# pse84_a0 register map
Vendor: Infineon Technologies; Series: PSE84_A0; File version: 1.0
CPU: CM33 r0p1, little endian, MPU, FPU, VTOR, 3 interrupt priority bits
Registers are 32-bit, read-write, reset 0x0 unless marked. A register's access mark holds for its fields unless they carry their own. Offsets are from the block's base; [hi:lo] are bit positions; {n}, {i} and the like mark numbered series; 'fields as' and 'values as' point back to an identical list.

## RAMC_PPU0 — Power Policy Unit Registers for System RAM
Base 0x42220000
Same registers: RAMC_PPU1 0x42221000
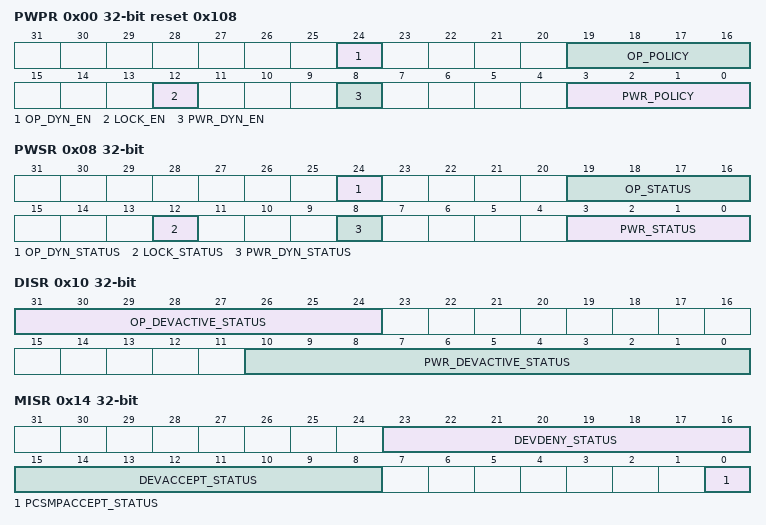
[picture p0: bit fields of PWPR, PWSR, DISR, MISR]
0x00 PWPR reset 0x108 — Power Policy Register
  [24] OP_DYN_EN
  [19:16] OP_POLICY
  [12] LOCK_EN
  [8] PWR_DYN_EN — Power mode dynamic transition enable. When this bit is set to 1 dynamic transitions are enabled for power modes, allowing transitions to be initiated by changes on power mode DEVACTIVE inputs.
  [3:0] PWR_POLICY — Power mode policy. When static power mode transitions are enabled, PWR_DYN_EN is set to 0, this is the target power mode for the PPU. When dynamic power mode transitions are enabled, PWR_DYN_EN is set to 1, this is the minimum power mode for the PPU. This PPU supports the following modes: OFF(0), MEM_RET(2), ON(8). Do not use WARM_RST(9) or other unsupported modes.
0x04 PMER — Power Mode Emulation Register
  [0] EMU_EN
0x08 PWSR ro — Power Status Register
  [24] OP_DYN_STATUS
  [19:16] OP_STATUS
  [12] LOCK_STATUS
  [8] PWR_DYN_STATUS — Power mode dynamic transition status. When set to 1 power mode dynamic transitions are enabled. There might be a delay in dynamic transitions becoming active or inactive if the PPU is transitioning when PWR_DYN_EN is programmed.
  [3:0] PWR_STATUS — Power mode status. These bits reflect the current power mode of the PPU. See PPU_PWPR.PWR_POLICY for power mode enumeration.
0x10 DISR ro — Device Interface Input Current Status Register
  [31:24] OP_DEVACTIVE_STATUS
  [10:0] PWR_DEVACTIVE_STATUS — Status of the power mode DEVACTIVE inputs. There is one bit for each device interface Q-Channel DEVQACTIVE. For example, bit 0 is for Q-channel device 0 DEVQACTIVE. Refer to PPU_IDR0.DEVCHAN for device channel enumeration.
0x14 MISR ro — Miscellaneous Input Current Status Register
  [23:16] DEVDENY_STATUS — Status of the device interface DEVDENY inputs. There is one bit for each device interface DEVQDENY. For example, bit 16 is for Q-Channel 0 DEVQDENY, and bit 17 for Q-Channel 1 DEVQDENY. Refer to PPU_IDR0.DEVCHAN for device channel enumeration.
  [15:8] DEVACCEPT_STATUS — Status of the device interface DEVACCEPT inputs. There is one bit for each device interface DEVQACCEPTn. For example, bit 8 is for Q-Channel 0 DEVQACCEPTn and bit 9 for Q-Channel 1 DEVQACCEPTn. Refer to PPU_IDR0.DEVCHAN for device channel enumeration.
  [0] PCSMPACCEPT_STATUS — The status of the PCSMPACCEPT input.
0x18 STSR ro — Stored Status Register
  [7:0] STORED_DEVDENY
0x1C UNLK — Unlock register
  [0] UNLOCK
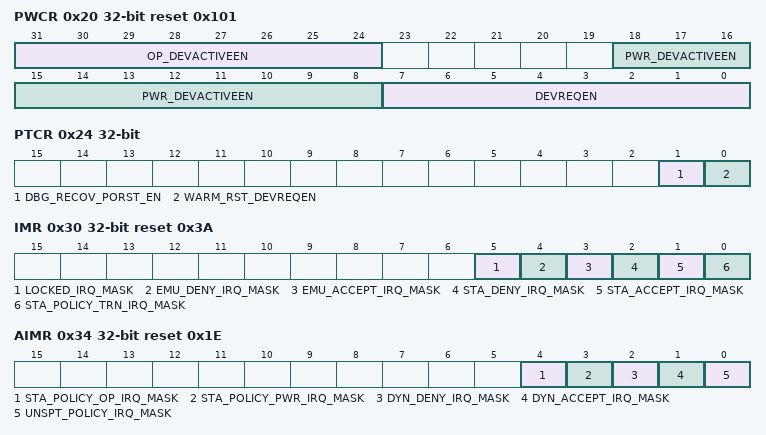
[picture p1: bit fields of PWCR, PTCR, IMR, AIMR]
0x20 PWCR reset 0x101 — Power Configuration Register
  [31:24] OP_DEVACTIVEEN
  [18:8] PWR_DEVACTIVEEN — These bits enable the power mode DEVACTIVE inputs. When a bit is to 1 the related DEVACTIVE input is enabled, when set to 0 it is disabled. All available bits are reset to 1. There is one bit for each device interface Q-Channel DEVQACTIVE. For example, bit 8 is for the Q-Channel 0 DEVQACTIVE, and bit 9 for the Q-Channel 1 DEVQACTIVE. Refer to PPU_IDR0.DEVCHAN for device channel enumeration.
  [7:0] DEVREQEN — When set to 1 enables the device interface handshake for transitions. All available bits are reset to 1. There is one bit for each device interface channel. For example, bit 0 is for Q-Channel 0, and bit 1 is for Q-Channel 1. Refer to PPU_IDR0.DEVCHAN for device channel enumeration.
0x24 PTCR — Power Mode Transition Configuration Register
  [1] DBG_RECOV_PORST_EN
  [0] WARM_RST_DEVREQEN — Transition behavior between ON and WARM_RST. This bit should not be modified when the PPU is in WARM_RST, or if the PPU is performing a transition, otherwise PPU behavior is UNPREDICTABLE. 0: The PPU does not perform a device interface handshake when transitioning between ON and WARM_RST. 1: The PPU performs a device interface handshake when transitioning between ON and WARM_RST. This disables all Q-Channels for this transition.
0x30 IMR reset 0x3A — Interrupt Mask Register
  [5] LOCKED_IRQ_MASK
  [4] EMU_DENY_IRQ_MASK
  [3] EMU_ACCEPT_IRQ_MASK
  [2] STA_DENY_IRQ_MASK — Static transition denial event mask.
  [1] STA_ACCEPT_IRQ_MASK — Static transition acceptance event mask.
  [0] STA_POLICY_TRN_IRQ_MASK — Static full policy transition completion event mask.
0x34 AIMR reset 0x1E — Additional Interrupt Mask Register
  [4] STA_POLICY_OP_IRQ_MASK
  [3] STA_POLICY_PWR_IRQ_MASK
  [2] DYN_DENY_IRQ_MASK — Dynamic transition denial event mask.
  [1] DYN_ACCEPT_IRQ_MASK — Dynamic transition acceptance event mask.
  [0] UNSPT_POLICY_IRQ_MASK — Unsupported Policy event mask.
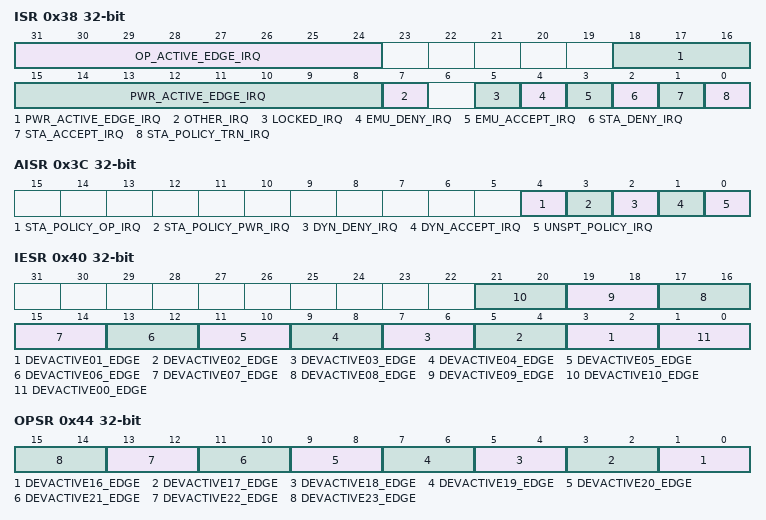
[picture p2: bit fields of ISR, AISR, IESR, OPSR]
0x38 ISR — Interrupt Status Register
  [31:24] OP_ACTIVE_EDGE_IRQ
  [18:8] PWR_ACTIVE_EDGE_IRQ
  [7] OTHER_IRQ ro — Indicates there is an interrupt event pending in the Additional Interrupt Status Register (PPU_AISR).
  [5] LOCKED_IRQ
  [4] EMU_DENY_IRQ
  [3] EMU_ACCEPT_IRQ
  [2] STA_DENY_IRQ — Static transition denial event status.
  [1] STA_ACCEPT_IRQ — Static transition acceptance event status.
  [0] STA_POLICY_TRN_IRQ — Static full policy transition completion event status.
0x3C AISR — Additional Interrupt Status Register
  [4] STA_POLICY_OP_IRQ
  [3] STA_POLICY_PWR_IRQ
  [2] DYN_DENY_IRQ — Dynamic transition denial event status.
  [1] DYN_ACCEPT_IRQ — Dynamic transition acceptance event status.
  [0] UNSPT_POLICY_IRQ — Unsupported Policy event status.
0x40 IESR — Input Edge Sensitivity Register
  [2n+1:2n] DEVACTIVE{n:02}_EDGE (n=1..10)
  [1:0] DEVACTIVE00_EDGE — DEVACTIVE 0 edge sensitivity.
0x44 OPSR — Operating Mode Active Edge Sensitivity Register
  [2n-31:2n-32] DEVACTIVE{n}_EDGE (n=16..23)
0x50 FUNRR — Functional Retention RAM Configuration Register
  [7:0] FUNC_RET_RAM_CFG
0x54 FULRR — Full Retention RAM Configuration Register
  [7:0] FULL_RET_RAM_CFG
0x58 MEMRR — Memory Retention RAM Configuration Register
  [7:0] MEM_RET_RAM_CFG
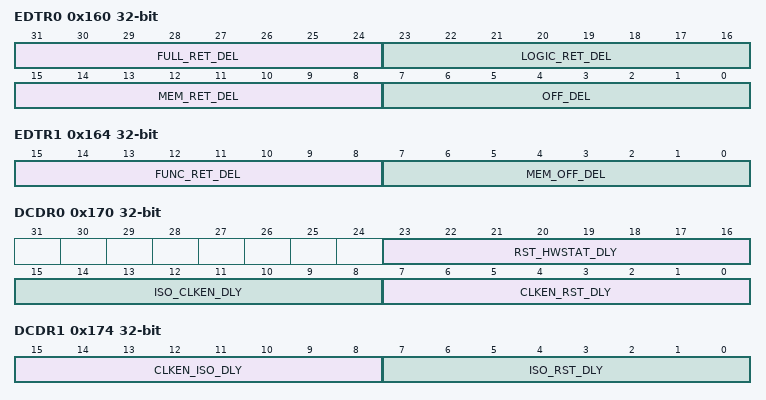
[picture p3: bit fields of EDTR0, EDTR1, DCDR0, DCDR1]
0x160 EDTR0 — Power Mode Entry Delay Register 0
  [31:24] FULL_RET_DEL, [23:16] LOGIC_RET_DEL, [15:8] MEM_RET_DEL, [7:0] OFF_DEL
0x164 EDTR1 — Power Mode Entry Delay Register 1
  [15:8] FUNC_RET_DEL, [7:0] MEM_OFF_DEL
0x170 DCDR0 ro — Device Control Delay Configuration Register 0
  [23:16] RST_HWSTAT_DLY, [15:8] ISO_CLKEN_DLY, [7:0] CLKEN_RST_DLY
0x174 DCDR1 ro — Device Control Delay Configuration Register 1
  [15:8] CLKEN_ISO_DLY, [7:0] ISO_RST_DLY
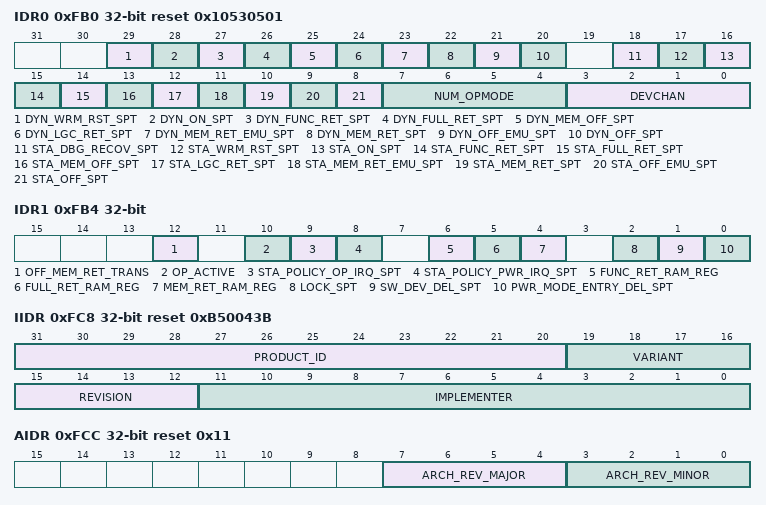
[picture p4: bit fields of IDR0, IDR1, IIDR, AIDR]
0xFB0 IDR0 ro reset 0x10530501 — PPU Identification Register 0
  [29] DYN_WRM_RST_SPT — Dynamic WARM_RST support.
  [28] DYN_ON_SPT — Dynamic ON support.
  [27] DYN_FUNC_RET_SPT — Dynamic FUNC_RET support.
  [26] DYN_FULL_RET_SPT — Dynamic FULL_RET support.
  [25] DYN_MEM_OFF_SPT — Dynamic MEM_OFF support.
  [24] DYN_LGC_RET_SPT — Dynamic LOGIC_RET support.
  [23] DYN_MEM_RET_EMU_SPT — Dynamic MEM_RET_EMU support
  [22] DYN_MEM_RET_SPT — Dynamic MEM_RET support.
  [21] DYN_OFF_EMU_SPT — Dynamic OFF_EMU support.
  [20] DYN_OFF_SPT — Dynamic OFF support.
  [18] STA_DBG_RECOV_SPT — DBG_RECOV support.
  [17] STA_WRM_RST_SPT — WARM_RST support. Ignore this bit. Do not use WARM_RST.
  [16] STA_ON_SPT — ON support.
  [15] STA_FUNC_RET_SPT — FUNC_RET support.
  [14] STA_FULL_RET_SPT — FULL_RET support.
  [13] STA_MEM_OFF_SPT — MEM_OFF support.
  [12] STA_LGC_RET_SPT — LOGIC_RET support.
  [11] STA_MEM_RET_EMU_SPT — MEM_RET_EMU support.
  [10] STA_MEM_RET_SPT — MEM_RET support.
  [9] STA_OFF_EMU_SPT — OFF_EMU support.
  [8] STA_OFF_SPT — OFF support.
  [7:4] NUM_OPMODE — No. of operating modes supported is NUM_OPMODE + 1.
  [3:0] DEVCHAN — No. of Device Interface Channels. The device enumeration is: Device 0: PDCM
0xFB4 IDR1 ro — PPU Identification Register 1
  [12] OFF_MEM_RET_TRANS — OFF to MEM_RET direct transition. Indicates if direct transitions from OFF to MEM_RET and from OFF_EMU to MEM_RET_EMU are supported.
  [10] OP_ACTIVE
  [9] STA_POLICY_OP_IRQ_SPT — Operating policy transition completion event status.
  [8] STA_POLICY_PWR_IRQ_SPT — Power policy transition completion event status.
  [6] FUNC_RET_RAM_REG
  [5] FULL_RET_RAM_REG
  [4] MEM_RET_RAM_REG
  [2] LOCK_SPT — Lock and the lock interrupt event are supported.
  [1] SW_DEV_DEL_SPT — Software device delay control configuration support.
  [0] PWR_MODE_ENTRY_DEL_SPT — Power mode entry delay support.
0xFC8 IIDR ro reset 0xB50043B — Implementation Identification Register
  [31:20] PRODUCT_ID — PPU part identification.
  [19:16] VARIANT — Major revision of the product.
  [15:12] REVISION — Minor revision of the product.
  [11:0] IMPLEMENTER — Implementer identification. [11:8] The JEP106 continuation code of the implementer. [7] Always 0. [6:0] The JEP106 identity code of the implementer. For an Arm implementation, bits [11:0] are 0x43B.
0xFCC AIDR ro reset 0x11 — Architecture Identification Register
  [7:4] ARCH_REV_MAJOR, [3:0] ARCH_REV_MINOR
0xFD0 PID4 ro reset 0x4 — Implementation Defined Identification Register (PID4)
  [3:0] IMPLEMENTER_11_8 — The JEP106 continuation code of the implementer, which is 0x4 hardcoded value.
0xFE0 PID0 ro reset 0xB5 — Implementation Defined Identification Register (PID0)
  [7:0] PRODUCT_ID_7_0 — PPU part identification bits [7:0].
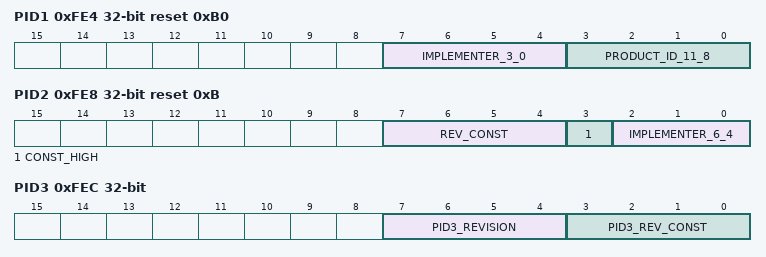
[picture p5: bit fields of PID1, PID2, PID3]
0xFE4 PID1 ro reset 0xB0 — Implementation Defined Identification Register (PID1)
  [7:4] IMPLEMENTER_3_0 — JEP106_ID bits [3:0]
  [3:0] PRODUCT_ID_11_8 — PPU part identification bits [11:8]
0xFE8 PID2 ro reset 0xB — Implementation Defined Identification Register (PID2)
  [7:4] REV_CONST — Constant LOW Revision (4 bits)
  [3] CONST_HIGH — Constant HIGH
  [2:0] IMPLEMENTER_6_4 — JEP106_ID bits [6:4]
0xFEC PID3 ro — Implementation Defined Identification Register (PID3)
  [7:4] PID3_REVISION — Minor revision of the product.
  [3:0] PID3_REV_CONST — Constant LOW (4 bits)
0xFF0 ID0 ro reset 0xD — Implementation Defined Identification Register (ID0)
  [7:0] ID0 — ID0 hard coded value
0xFF4 ID1 ro reset 0xF0 — Implementation Defined Identification Register (ID1)
  [7:0] ID1 — ID1 hardcoded value
0xFF8 ID2 ro reset 0x5 — Implementation Defined Identification Register (ID2)
  [7:0] ID2 — ID2 hardcoded value
0xFFC ID3 ro reset 0xB1 — Implementation Defined Identification Register (ID3)
  [7:0] ID3 — ID3 hardcoded value

## CPUSS_PPU — Power Policy Unit Registers for CPUSS
Base 0x42225000
Registers as RAMC_PPU0; these are added or differ:
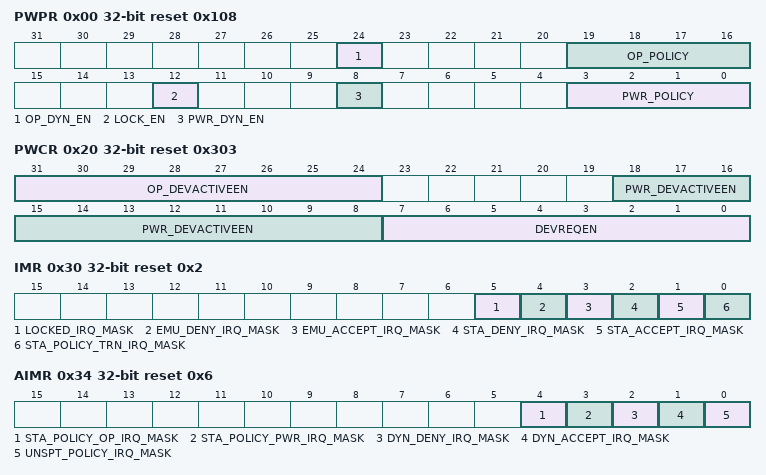
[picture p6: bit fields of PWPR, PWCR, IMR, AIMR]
0x00 PWPR reset 0x108 — Power Policy Register
  [24] OP_DYN_EN
  [19:16] OP_POLICY
  [12] LOCK_EN
  [8] PWR_DYN_EN — Power mode dynamic transition enable. When this bit is set to 1 dynamic transitions are enabled for power modes, allowing transitions to be initiated by changes on power mode DEVACTIVE inputs.
  [3:0] PWR_POLICY — Power mode policy. When static power mode transitions are enabled, PWR_DYN_EN is set to 0, this is the target power mode for the PPU. When dynamic power mode transitions are enabled, PWR_DYN_EN is set to 1, this is the minimum power mode for the PPU. This PPU supports the following modes: OFF(0), FULL_RET(5), ON(8). Do not use WARM_RST(9) or other unsupported modes.
0x18 STSR ro — Stored Status Register
  [7:0] STORED_DEVDENY — Status of the DEVDENY signals from the last device interface Q-Channel transition. For Q-Channel: There is one bit for each device interface DEVQDENY. For example, bit 0 is for Q-Channel 0 DEVQDENY, and bit 1 for Q-Channel 1 DEVQDENY. Refer to PPU_DISR.PWR_DEVACTIVE_STATUS for device enumeration.
0x20 PWCR reset 0x303 — Power Configuration Register
  fields as RAMC_PPU0.PWCR
0x30 IMR reset 0x2 — Interrupt Mask Register
  fields as RAMC_PPU0.IMR
0x34 AIMR reset 0x6 — Additional Interrupt Mask Register
  fields as RAMC_PPU0.AIMR
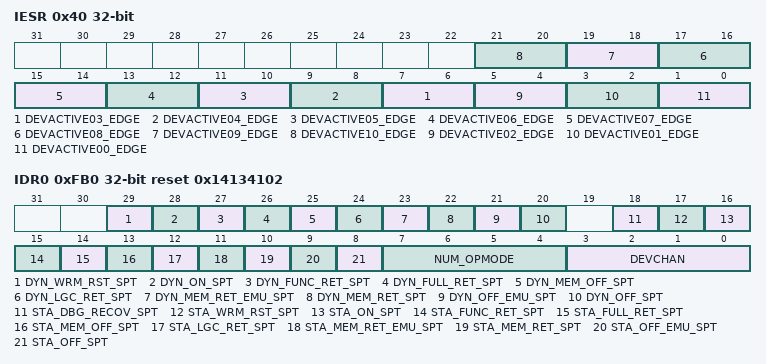
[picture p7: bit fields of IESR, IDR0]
0x40 IESR — Input Edge Sensitivity Register
  [2n+1:2n] DEVACTIVE{n:02}_EDGE (n=3..10)
  [5:4] DEVACTIVE02_EDGE — DEVACTIVE 2 edge sensitivity.
  [3:2] DEVACTIVE01_EDGE — DEVACTIVE 1 edge sensitivity.
  [1:0] DEVACTIVE00_EDGE — DEVACTIVE 0 edge sensitivity.
0xFB0 IDR0 ro reset 0x14134102 — PPU Identification Register 0
  [29] DYN_WRM_RST_SPT — Dynamic WARM_RST support.
  [28] DYN_ON_SPT — Dynamic ON support.
  [27] DYN_FUNC_RET_SPT — Dynamic FUNC_RET support.
  [26] DYN_FULL_RET_SPT — Dynamic FULL_RET support.
  [25] DYN_MEM_OFF_SPT — Dynamic MEM_OFF support.
  [24] DYN_LGC_RET_SPT — Dynamic LOGIC_RET support.
  [23] DYN_MEM_RET_EMU_SPT — Dynamic MEM_RET_EMU support
  [22] DYN_MEM_RET_SPT — Dynamic MEM_RET support.
  [21] DYN_OFF_EMU_SPT — Dynamic OFF_EMU support.
  [20] DYN_OFF_SPT — Dynamic OFF support.
  [18] STA_DBG_RECOV_SPT — DBG_RECOV support.
  [17] STA_WRM_RST_SPT — WARM_RST support. Ignore this bit. Do not use WARM_RST.
  [16] STA_ON_SPT — ON support.
  [15] STA_FUNC_RET_SPT — FUNC_RET support.
  [14] STA_FULL_RET_SPT — FULL_RET support.
  [13] STA_MEM_OFF_SPT — MEM_OFF support.
  [12] STA_LGC_RET_SPT — LOGIC_RET support.
  [11] STA_MEM_RET_EMU_SPT — MEM_RET_EMU support.
  [10] STA_MEM_RET_SPT — MEM_RET support.
  [9] STA_OFF_EMU_SPT — OFF_EMU support.
  [8] STA_OFF_SPT — OFF support.
  [7:4] NUM_OPMODE — No. of operating modes supported is NUM_OPMODE + 1.
  [3:0] DEVCHAN — No. of Device Interface Channels. 0: This is a P-Channel PPU. Refer to PPU_IDR1.OP_ACTIVE for the number of DEVPACTIVE inputs and their meaning. non-zero: The value is the number of Q-Channels. The device enumeration is: Device 0: SRSS PDCM, Device 1: CPUSS SEQ between SS level LPD500 EXP & PERI Q-Channel

## PPU_APPCPUSS — Power Policy Unit Registers for APPCPUSS PPU
Base 0x44100000
Registers as CPUSS_PPU; these are added or differ:
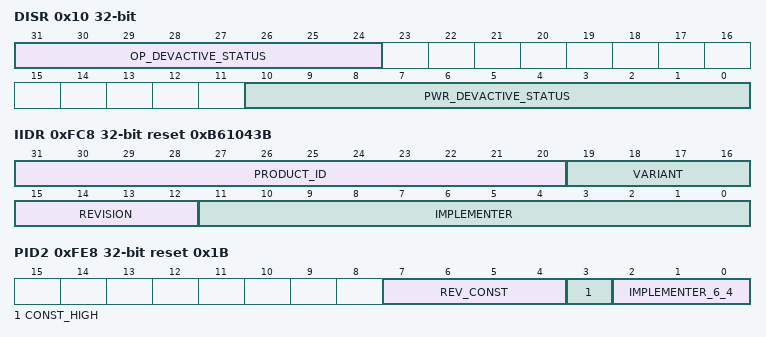
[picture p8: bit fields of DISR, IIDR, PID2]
0x10 DISR ro — Device Interface Input Current Status Register
  [31:24] OP_DEVACTIVE_STATUS, [10:0] PWR_DEVACTIVE_STATUS
0xFC8 IIDR ro reset 0xB61043B — Implementation Identification Register
  fields as RAMC_PPU0.IIDR
0xFE0 PID0 ro reset 0xB6 — Implementation Defined Identification Register (PID0)
  [7:0] PRODUCT_ID_7_0 — PPU part identification bits [7:0].
0xFE8 PID2 ro reset 0x1B — Implementation Defined Identification Register (PID2)
  [7:4] REV_CONST — Revision 1(4 bits)
  [3] CONST_HIGH — Constant HIGH
  [2:0] IMPLEMENTER_6_4 — JEP106_ID bits [6:4]

## PPU_CM55_0 — Power Policy Unit Registers for CM55_0 PPU
Base 0x44101000
Registers as PPU_APPCPUSS; these are added or differ:
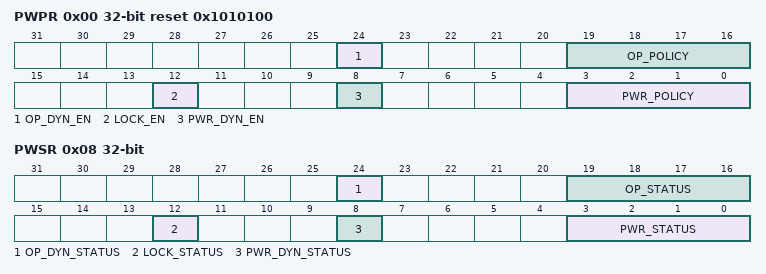
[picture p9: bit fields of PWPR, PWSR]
0x00 PWPR reset 0x1010100 — Power Policy Register
  [24] OP_DYN_EN — Operating mode dynamic transition enable. When this bit is set to 0b1 dynamic transitions are enabled for operating modes, allowing transitions to be initiated by changes on operating mode DEVACTIVE inputs.
  [19:16] OP_POLICY — Operating mode policy. When static operating mode transitions are enabled,OP_DYN_EN is set to 0b0, then this is the target operating mode for the PPU. When dynamic operating mode transitions are enabled,OP_DYN_EN is set to 0b1, then this is the minimum operating mode for the PPU.
  [12] LOCK_EN
  [8] PWR_DYN_EN — Power mode dynamic transition enable. When this bit is set to 1 dynamic transitions are enabled for power modes, allowing transitions to be initiated by changes on power mode DEVACTIVE inputs.
  [3:0] PWR_POLICY — Power mode policy. When static power mode transitions are enabled, PWR_DYN_EN is set to 0, this is the target power mode for the PPU. When dynamic power mode transitions are enabled, PWR_DYN_EN is set to 1, this is the minimum power mode for the PPU. This PPU supports the following modes: OFF(0), FULL_RET(5), ON(8). Do not use WARM_RST(9) or other unsupported modes.
0x08 PWSR ro — Power Status Register
  [24] OP_DYN_STATUS — Operating mode dynamic transition enable. When this bit is set to 0b1 dynamic transitions are enabled for operating modes, allowing transitions to be initiated by changes on operating mode DEVACTIVE inputs.
  [19:16] OP_STATUS — Operating mode policy. When static operating mode transitions are enabled,OP_DYN_EN is set to 0b0, then this is the target operating mode for the PPU. When dynamic operating mode transitions are enabled,OP_DYN_EN is set to 0b1, then this is the minimum operating mode for the PPU.
  [12] LOCK_STATUS
  [8] PWR_DYN_STATUS — Power mode dynamic transition status. When set to 1 power mode dynamic transitions are enabled. There might be a delay in dynamic transitions becoming active or inactive if the PPU is transitioning when PWR_DYN_EN is programmed.
  [3:0] PWR_STATUS — Power mode status. These bits reflect the current power mode of the PPU. See PPU_PWPR.PWR_POLICY for power mode enumeration.

## Notices in the file
(c) (2016-2025), Cypress Semiconductor Corporation (an Infineon company)
or an affiliate of Cypress Semiconductor Corporation.
SPDX-License-Identifier: Apache-2.0
Licensed under the Apache License, Version 2.0 (the "License");
you may not use this file except in compliance with the License.
You may obtain a copy of the License at
http://www.apache.org/licenses/LICENSE-2.0
Unless required by applicable law or agreed to in writing, software
distributed under the License is distributed on an "AS IS" BASIS,
WITHOUT WARRANTIES OR CONDITIONS OF ANY KIND, either express or implied.
See the License for the specific language governing permissions and
limitations under the License.
